# nrf7120_enga_application register map
Vendor: Nordic Semiconductor; Series: nrf71; File version: 1
CPU: CM33 r0p4, little endian, MPU, FPU, 3 interrupt priority bits, 270 interrupts, 4 SAU regions
Registers are 32-bit, read-write, reset 0x0 unless marked. A register's access mark holds for its fields unless they carry their own. Offsets are from the block's base; [hi:lo] are bit positions; lines under a group give offsets from that group; {n}, {i} and the like mark numbered series; 'fields as' and 'values as' point back to an identical list.

## GLOBAL_SPU00_S — System protection unit 0
Base 0x50040000; alternate view of GLOBAL_USBHSCORE_S
Same registers: GLOBAL_SPU10_S 0x50080000, GLOBAL_SPU20_S 0x500C0000, GLOBAL_SPU30_S 0x50100000
0x100 EVENTS_PERIPHACCERR — A security violation has been detected on one or several peripherals
  [0] EVENTS_PERIPHACCERR
    0=NotGenerated (Event not generated); 1=Generated (Event generated)
0x300 INTEN — Enable or disable interrupt
  [0] PERIPHACCERR — Enable or disable interrupt for event PERIPHACCERR
    0=Disabled; 1=Enabled
0x304 INTENSET — Enable interrupt
  [0] PERIPHACCERR — Write '1' to enable interrupt for event PERIPHACCERR
    on read: 0=Disabled (Read: Disabled); 1=Enabled (Read: Enabled) | on write: 1=Set (Enable)
0x308 INTENCLR — Disable interrupt
  [0] PERIPHACCERR — Write '1' to disable interrupt for event PERIPHACCERR
    on read: 0=Disabled (Read: Disabled); 1=Enabled (Read: Enabled) | on write: 1=Clear (Disable)
0x30C INTPEND ro — Pending interrupts
  [0] PERIPHACCERR — Read pending status of interrupt for event PERIPHACCERR
    on read: 0=NotPending (Read: Not pending); 1=Pending (Read: Pending)
0x404 PERIPHACCERR group — Unspecified
  0x00 ADDRESS ro — Address of the transaction that caused first error.
    [15:0] ADDRESS
{0x500+4i} PERIPH[{i}] (i=0..63) group — Unspecified
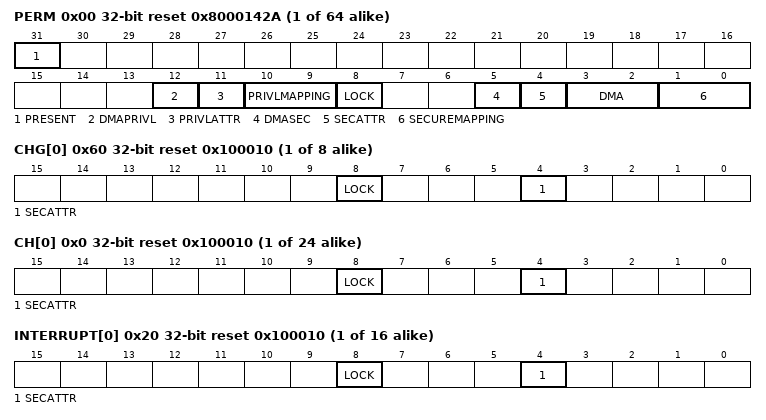
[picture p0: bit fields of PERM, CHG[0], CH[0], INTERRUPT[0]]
  0x00 PERM reset 0x8000142A — Description cluster: Get and set the applicable access permissions for the peripheral slave index n
    [31] PRESENT ro — Indicates if a peripheral is present with peripheral slave index n
      0=NotPresent (Peripheral is not present); 1=IsPresent (Peripheral is present)
    [12] DMAPRIVL — Privilege attribution for peripheral DMA transfers
      1=Privileged (DMA transfers initiated by this peripheral have the Privilege attribute set); 0=Unprivileged (DMA transfers initiated by this peripheral have the Unprivileged attribute set)
    [11] PRIVLATTR — Peripheral privilege mapping
      1=Privileged (Peripheral is Privileged); 0=Unprivileged (Peripheral is Unprivileged or Split Privilege)
    [10:9] PRIVLMAPPING ro — Capabilities for Privilege mapping
      0=Unprivileged (This peripheral is always Unprivileged); 1=Privileged (This peripheral is always Privileged); 2=UserSelectable (Privileged or Unprivileged attribute for this peripheral is defined by the PERIPH[n].PERM.PRIVLATTR register); 3=Split (This peripheral implements Split Privilege)
    [8] LOCK write-1-sets
      0=Unlocked (This register can be updated); 1=Locked (The content of this register can not be changed until the next reset)
    [5] DMASEC — Security attribution for the DMA transfer
      1=Secure (DMA transfers initiated by this peripheral have the secure attribute set); 0=NonSecure (DMA transfers initiated by this peripheral have the non-secure attribute set)
    [4] SECATTR — Peripheral security mapping
      1=Secure (Peripheral is mapped in secure peripheral address space); 0=NonSecure (If SECUREMAPPING == UserSelectable: Peripheral is mapped in non-secure peripheral address space. If SECUREMAPPING == Split: Peripheral is mapped in non-secure and secure peripheral address space.)
    [3:2] DMA ro — Read the peripheral DMA capabilities
      0=NoDMA (Peripheral has no DMA capability); 1=NoSeparateAttribute (Peripheral has DMA and DMA transfers always have the same security attribute as assigned to the peripheral); 2=SeparateAttribute (Peripheral has DMA and DMA transfers can have a different security attribute than the one assigned to the peripheral)
    [1:0] SECUREMAPPING ro — Read capabilities for TrustZone Cortex-M secure attribute
      0=NonSecure (This peripheral is always accessible as a non-secure peripheral); 1=Secure (This peripheral is always accessible as a secure peripheral); 2=UserSelectable (Non-secure or secure attribute for this peripheral is defined by the PERIPH[n].PERM register); 3=Split (This peripheral implements the split security mechanism.)
0x600 FEATURE group — Unspecified
  0x80 DPPIC group — Unspecified
    {0x0+4k} CH[{k}] (k=0..23) reset 0x100010 — Description collection: Security configuration for channel n of DPPIC
      [8] LOCK write-1-sets — LOCK feature
        0=Unlocked (Feature permissions can be updated); 1=Locked (Feature permissions can not be changed until the next reset)
      [4] SECATTR — SECATTR feature
        0=NonSecure (Feature is available for non-secure usage); 1=Secure (Feature is reserved for secure usage)
    {0x60+4k} CHG[{k}] (k=0..7) reset 0x100010 — Description collection: Security configuration for channel group n of DPPIC
      fields as FEATURE.DPPIC.CH[0]
  {0x100+0x40*j} GPIOTE[{j}] (j=0..1) group — Unspecified
    {0x0+4k} CH[{k}] (k=0..7) reset 0x100010 — Description collection: Security configuration for channel o of GPIOTE[n]
      fields as FEATURE.DPPIC.CH[0]
    {0x20+4k} INTERRUPT[{k}] (k=0..7) reset 0x100010 — Description collection: Security configuration for interrupt o of GPIOTE[n]
      fields as FEATURE.DPPIC.CH[0]
  0x100 COEXC group (alternate view of GPIOTE[*]) — Unspecified
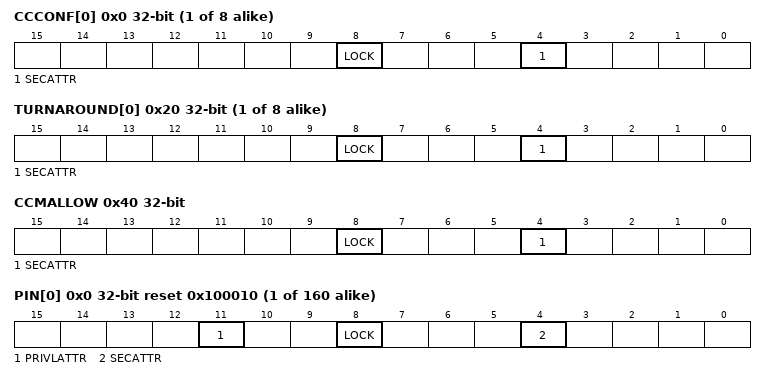
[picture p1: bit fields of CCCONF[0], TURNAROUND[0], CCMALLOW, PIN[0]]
    {0x0+4k} CCCONF[{k}] (k=0..7) — Description collection: Configuration of features for CCCONF[n] of COEXC
      fields as FEATURE.DPPIC.CH[0]
    {0x20+4k} TURNAROUND[{k}] (k=0..7) — Description collection: Configuration of features for TURNAROUND[n] of COEXC
      fields as FEATURE.DPPIC.CH[0]
    0x40 CCMALLOW — Configuration of features for CCMALLOW of COEXC
      fields as FEATURE.DPPIC.CH[0]
  {0x200+0x80*j} GPIO[{j}] (j=0..4) group — Unspecified
    {0x0+4k} PIN[{k}] (k=0..31) reset 0x100010 — Description collection: Security configuration for GPIO[n] PIN[o]
      [11] PRIVLATTR — PRIVLATTR feature
        0=Unprivileged (Feature is available for Unprivileged usage); 1=Privileged (Feature is reserved for Privileged usage)
      [8] LOCK write-1-sets — LOCK feature
        values as FEATURE.DPPIC.CH[0].LOCK
      [4] SECATTR — SECATTR feature
        values as FEATURE.DPPIC.CH[0].SECATTR
  0x200 CRACEN group (alternate view of GPIO[*]) — Unspecified
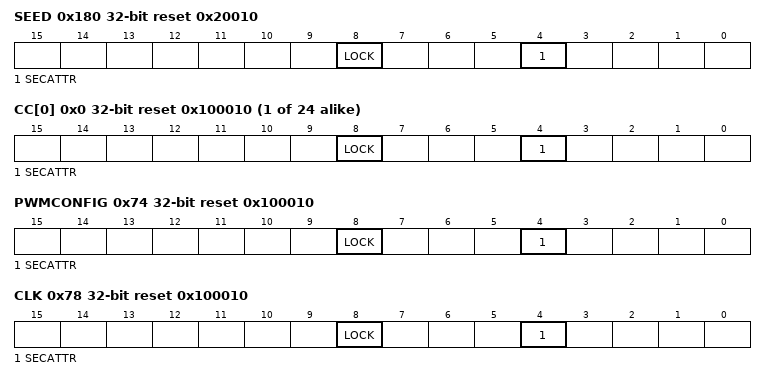
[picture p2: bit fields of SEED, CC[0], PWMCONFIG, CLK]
    0x180 SEED reset 0x20010 — Configuration for CRACEN SEED
      fields as FEATURE.DPPIC.CH[0]
  0x700 GRTC group — Unspecified
    {0x0+4k} CC[{k}] (k=0..23) reset 0x100010 — Description collection: Security configuration for CC n of GRTC
      fields as FEATURE.DPPIC.CH[0]
    0x74 PWMCONFIG reset 0x100010 — Security Configuration for PWMCONFIG of GRTC
      fields as FEATURE.DPPIC.CH[0]
    0x78 CLK reset 0x100010 — Security configuration for CLKOUT/CLKCFG of GRTC
      fields as FEATURE.DPPIC.CH[0]
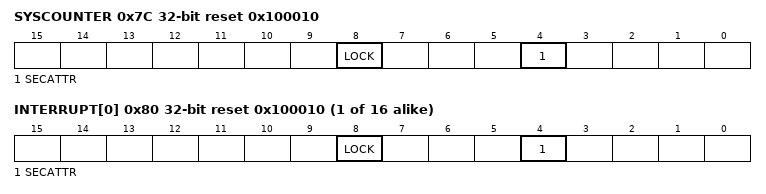
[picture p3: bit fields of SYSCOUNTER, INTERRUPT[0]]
    0x7C SYSCOUNTER reset 0x100010 — Security configuration for SYSCOUNTERL/SYSCOUNTERH of GRTC
      fields as FEATURE.DPPIC.CH[0]
    {0x80+4k} INTERRUPT[{k}] (k=0..15) reset 0x100010 — Description collection: Security configuration for interrupt n of GRTC
      fields as FEATURE.DPPIC.CH[0]
